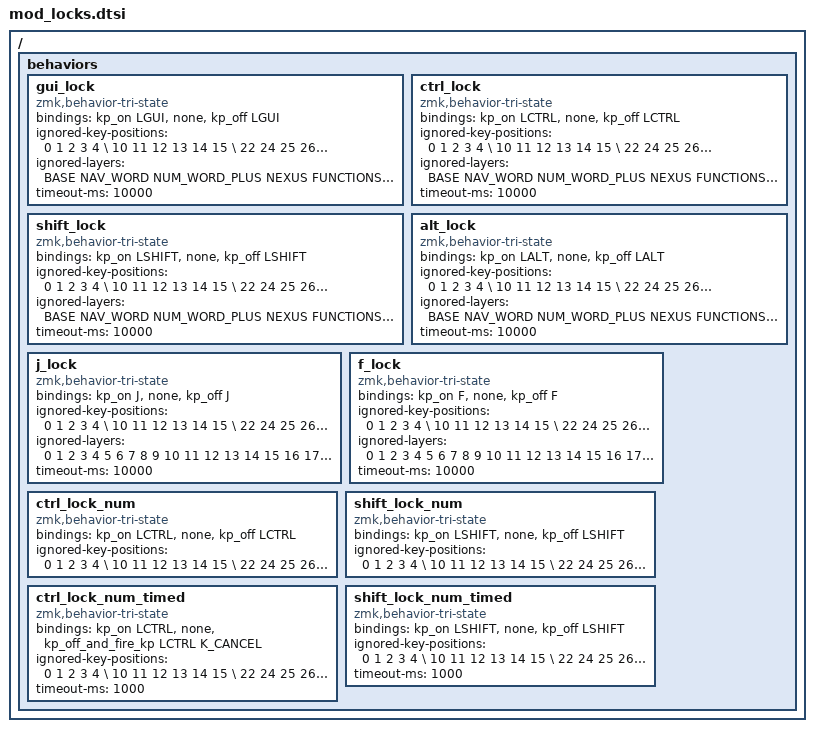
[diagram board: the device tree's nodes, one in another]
/ {
	behaviors {
		
		gui_lock: gui_lock {
			compatible = "zmk,behavior-tri-state";
			#binding-cells = <0>;
			/* bindings = <&kp_on_and_layer LGUI KCAN_OVER>, <&none>, <&kp_off_and_layer LGUI KCAN_OVER>; */
			bindings = <&kp_on LGUI>, <&none>, <&kp_off LGUI>;
			ignored-key-positions = <
			
			/* left hand */
			0  1  2  3  4      \
			10 11 12 13 14 15  \
			22    24 25 26 27  \
			34 35 36 37 38 39  \
			46 47 48 49 50 51  \
			64 65 66 67 68     \
			/* right hand */
			5  6  7  8  9      \
			16 17 18 19    21  \
			28 29 30 31 32 33  \
			40 41 42 43 44 45  \
			58 59 60 61 62 63  \
			75 76 77 78 79     \
			/* thumbs */
			69 52       57 74  \
			70           73    \
			71 54   55 72

			>;
			/* ignored-layers = <BASE CAPS_WORD_DOT NAV_WORD NUM_WORD NEXUS  FUNCTIONS ICE MOD_LOCKS MOUSE MOUSE_SLOW MOUSE_FAST MOUSE_WARP>; */
			ignored-layers = <BASE NAV_WORD NUM_WORD_PLUS NEXUS  FUNCTIONS ICE MOUSE MOUSE_SLOW MOUSE_FAST MOUSE_WARP>;
			timeout-ms = <10000>;
		};
		
		ctrl_lock: ctrl_lock {
			compatible = "zmk,behavior-tri-state";
			#binding-cells = <0>;
			/* bindings = <&kp_on_and_layer LCTRL KCAN_OVER>, <&none>, <&kp_off_and_layer LCTRL KCAN_OVER>; */
			bindings = <&kp_on LCTRL>, <&none>, <&kp_off LCTRL>;
			ignored-key-positions = <
			
			/* left hand */
			0  1  2  3  4      \
			10 11 12 13 14 15  \
			22    24 25 26 27  \
			34 35 36 37 38 39  \
			46 47 48 49 50 51  \
			64 65 66 67 68     \
			/* right hand */
			5  6  7  8  9      \
			16 17 18 19    21  \
			28 29 30 31 32 33  \
			40 41 42 43 44 45  \
			58 59 60 61 62 63  \
			75 76 77 78 79     \
			/* thumbs */
			69 52       57 74  \
			70           73    \
			71 54   55 72

			>;
			/* ignored-layers = <BASE CAPS_WORD_DOT NAV_WORD NUM_WORD NEXUS  FUNCTIONS ICE MOD_LOCKS MOUSE MOUSE_SLOW MOUSE_FAST MOUSE_WARP>; */
			ignored-layers = <BASE NAV_WORD NUM_WORD_PLUS NEXUS  FUNCTIONS ICE MOUSE MOUSE_SLOW MOUSE_FAST MOUSE_WARP>;
			timeout-ms = <10000>;
		};
		
		shift_lock: shift_lock {
			compatible = "zmk,behavior-tri-state";
			#binding-cells = <0>;
			/* bindings = <&kp_on_and_layer LSHIFT KCAN_OVER>, <&none>, <&kp_off_and_layer LSHIFT KCAN_OVER>; */
			bindings = <&kp_on LSHIFT>, <&none>, <&kp_off LSHIFT>;
			ignored-key-positions = <
			
			/* left hand */
			0  1  2  3  4      \
			10 11 12 13 14 15  \
			22    24 25 26 27  \
			34 35 36 37 38 39  \
			46 47 48 49 50 51  \
			64 65 66 67 68     \
			/* right hand */
			5  6  7  8  9      \
			16 17 18 19    21  \
			28 29 30 31 32 33  \
			40 41 42 43 44 45  \
			58 59 60 61 62 63  \
			75 76 77 78 79     \
			/* thumbs */
			69 52       57 74  \
			70           73    \
			71 54   55 72

			>;
			/* ignored-layers = <BASE CAPS_WORD_DOT NAV_WORD NUM_WORD NEXUS  FUNCTIONS ICE MOD_LOCKS MOUSE MOUSE_SLOW MOUSE_FAST MOUSE_WARP>; */
			ignored-layers = <BASE NAV_WORD NUM_WORD_PLUS NEXUS  FUNCTIONS ICE MOUSE MOUSE_SLOW MOUSE_FAST MOUSE_WARP>;
			timeout-ms = <10000>;
		};
		
		alt_lock: alt_lock {
			compatible = "zmk,behavior-tri-state";
			#binding-cells = <0>;
			/* bindings = <&kp_on_and_layer LALT KCAN_OVER>, <&none>, <&kp_off_and_layer LALT KCAN_OVER>; */
			bindings = <&kp_on LALT>, <&none>, <&kp_off LALT>;
			ignored-key-positions = <
			
			/* left hand */
			0  1  2  3  4      \
			10 11 12 13 14 15  \
			22    24 25 26 27  \
			34 35 36 37 38 39  \
			46 47 48 49 50 51  \
			64 65 66 67 68     \
			/* right hand */
			5  6  7  8  9      \
			16 17 18 19    21  \
			28 29 30 31 32 33  \
			40 41 42 43 44 45  \
			58 59 60 61 62 63  \
			75 76 77 78 79     \
			/* thumbs */
			69 52       57 74  \
			70           73    \
			71 54   55 72

			>;
			/* ignored-layers = <BASE CAPS_WORD_DOT NAV_WORD NUM_WORD NEXUS  FUNCTIONS ICE MOD_LOCKS MOUSE MOUSE_SLOW MOUSE_FAST MOUSE_WARP>; */
			ignored-layers = <BASE NAV_WORD NUM_WORD_PLUS NEXUS  FUNCTIONS ICE MOUSE MOUSE_SLOW MOUSE_FAST MOUSE_WARP>;
			timeout-ms = <10000>;
		};

		j_lock: j_lock {
			compatible = "zmk,behavior-tri-state";
			#binding-cells = <0>;
			/* bindings = <&kp_on_and_layer LALT KCAN_OVER>, <&none>, <&kp_off_and_layer LALT KCAN_OVER>; */
			bindings = <&kp_on J>, <&none>, <&kp_off J>;
			ignored-key-positions = <
			
			/* left hand */
			0  1  2  3  4      \
			10 11 12 13 14 15  \
			22    24 25 26 27  \
			34 35 36 37 38 39  \
			46 47 48 49 50 51  \
			64 65 66 67 68     \
			/* right hand */
			5  6  7  8  9      \
			16 17 18 19    21  \
			28 29 30 31 32 33  \
			40 41 42 43 44 45  \
			58 59 60 61 62 63  \
			75 76 77 78 79     \
			/* thumbs */
			69 52       57 74  \
			70           73    \
			71 54   55 72

			>;
			ignored-layers = <0 1 2 3 4 5 6 7 8 9 10 11 12 13 14 15 16 17 18 19 20 21 22 23 24 25 26 27 28 29 30 31>;
			timeout-ms = <10000>;
		};

		f_lock: f_lock {
			compatible = "zmk,behavior-tri-state";
			#binding-cells = <0>;
			/* bindings = <&kp_on_and_layer LALT KCAN_OVER>, <&none>, <&kp_off_and_layer LALT KCAN_OVER>; */
			bindings = <&kp_on F>, <&none>, <&kp_off F>;
			ignored-key-positions = <
			/* left hand */
			0  1  2  3  4      \
			10 11 12 13 14 15  \
			22    24 25 26 27  \
			34 35 36 37 38 39  \
			46 47 48 49 50 51  \
			64 65 66 67 68     \
			/* right hand */
			5  6  7  8  9      \
			16 17 18 19    21  \
			28 29 30 31 32 33  \
			40 41 42 43 44 45  \
			58 59 60 61 62 63  \
			75 76 77 78 79     \
			/* thumbs */
			69 52       57 74  \
			70           73    \
			71 54   55 72
			>;
			ignored-layers = <0 1 2 3 4 5 6 7 8 9 10 11 12 13 14 15 16 17 18 19 20 21 22 23 24 25 26 27 28 29 30 31>;
			timeout-ms = <10000>;
		};
		

		ctrl_lock_num: ctrl_lock_num {
			compatible = "zmk,behavior-tri-state";
			#binding-cells = <0>;
			/* bindings = <&kp_on_and_layer LCTRL KCAN_OVER>, <&none>, <&kp_off_and_layer LCTRL KCAN_OVER>; */
			bindings = <&kp_on LCTRL>, <&none>, <&kp_off LCTRL>;
			ignored-key-positions = <
			
			/* left hand */
			0  1  2  3  4      \
			10 11 12 13 14 15  \
			22    24 25 26 27  \
			34 35 36 37 38 39  \
			46 47 48 49 50 51  \
			64 65 66 67 68     \
			/* right hand */
			5  6  7  8  9      \
			16 17 18 19    21  \
			28 29 30 31 32 33  \
			40 41 42 43 44 45  \
			   59 60 61 62 63  \
			75 76 77 78 79     \
			/* thumbs */
			69 52       57 74  \
			70           73    \
			71 54   55 72

			>;
		};
		
		shift_lock_num: shift_lock_num {
			compatible = "zmk,behavior-tri-state";
			#binding-cells = <0>;
			/* bindings = <&kp_on_and_layer LSHIFT KCAN_OVER>, <&none>, <&kp_off_and_layer LSHIFT KCAN_OVER>; */
			bindings = <&kp_on LSHIFT>, <&none>, <&kp_off LSHIFT>;
			ignored-key-positions = <
			
			/* left hand */
			0  1  2  3  4      \
			10 11 12 13 14 15  \
			22    24 25 26 27  \
			34 35 36 37 38 39  \
			46 47 48 49 50 51  \
			64 65 66 67 68     \
			/* right hand */
			5  6  7  8  9      \
			16 17 18 19    21  \
			28 29 30 31 32 33  \
			40 41 42 43 44 45  \
			   59 60 61 62 63  \
			75 76 77 78 79     \
			/* thumbs */
			69 52       57 74  \
			70           73    \
			71 54   55 72

			>;
		};

		ctrl_lock_num_timed: ctrl_lock_num_timed {
			compatible = "zmk,behavior-tri-state";
			#binding-cells = <0>;
			/* bindings = <&kp_on_and_layer LCTRL KCAN_OVER>, <&none>, <&kp_off_and_layer LCTRL KCAN_OVER>; */
			bindings = <&kp_on LCTRL>, <&none>, <&kp_off_and_fire_kp LCTRL K_CANCEL>;
			ignored-key-positions = <
			
			/* left hand */
			0  1  2  3  4      \
			10 11 12 13 14 15  \
			22    24 25 26 27  \
			34 35 36 37 38 39  \
			46 47 48 49 50 51  \
			64 65 66 67 68     \
			/* right hand */
			5  6  7  8  9      \
			16 17 18 19    21  \
			28 29 30 31 32 33  \
			40 41 42 43 44 45  \
			   59 60 61 62 63  \
			75 76 77 78 79     \
			/* thumbs */
			69 52       57 74  \
			70           73    \
			71 54   55 72

			>;
			timeout-ms = <1000>;
		};
		
		shift_lock_num_timed: shift_lock_num_timed {
			compatible = "zmk,behavior-tri-state";
			#binding-cells = <0>;
			/* bindings = <&kp_on_and_layer LSHIFT KCAN_OVER>, <&none>, <&kp_off_and_layer LSHIFT KCAN_OVER>; */
			bindings = <&kp_on LSHIFT>, <&none>, <&kp_off LSHIFT>;
			ignored-key-positions = <
			
			/* left hand */
			0  1  2  3  4      \
			10 11 12 13 14 15  \
			22    24 25 26 27  \
			34 35 36 37 38 39  \
			46 47 48 49 50 51  \
			64 65 66 67 68     \
			/* right hand */
			5  6  7  8  9      \
			16 17 18 19    21  \
			28 29 30 31 32 33  \
			40 41 42 43 44 45  \
			   59 60 61 62 63  \
			75 76 77 78 79     \
			/* thumbs */
			69 52       57 74  \
			70           73    \
			71 54   55 72

			>;
			timeout-ms = <1000>;
		};
	};
};
